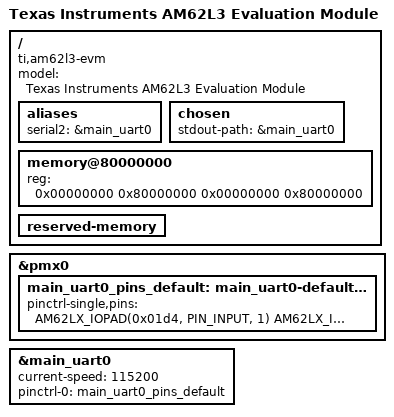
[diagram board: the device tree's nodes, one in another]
// SPDX-License-Identifier: GPL-2.0-only or MIT
/*
 * Device Tree file for the AM62L3 Evaluation Module
 * Copyright (C) 2024 Texas Instruments Incorporated - https://www.ti.com/
 *
 * Technical Reference Manual: https://www.ti.com/lit/ug/sprujb4/sprujb4.pdf
 */

/dts-v1/;

#include "k3-am62l3.dtsi"

/ {
	compatible = "ti,am62l3-evm", "ti,am62l3";
	model = "Texas Instruments AM62L3 Evaluation Module";

	aliases {
		serial2 = &main_uart0;
	};

	chosen {
		stdout-path = &main_uart0;
	};

	memory@80000000 {
		reg = <0x00000000 0x80000000 0x00000000 0x80000000>;
		device_type = "memory";
		bootph-all;
	};

	reserved-memory {
		ranges;
		#address-cells = <2>;
		#size-cells = <2>;
	};
};

&pmx0 {
	main_uart0_pins_default: main_uart0-default-pins {
		pinctrl-single,pins = <
			AM62LX_IOPAD(0x01d4, PIN_INPUT, 1)	  /* (D7)  UART0_RXD */
			AM62LX_IOPAD(0x01d8, PIN_OUTPUT, 1)	  /* (A6)  UART0_TXD */
		>;
		bootph-all;
	};
};

&main_uart0 {
	current-speed = <115200>;
	pinctrl-names = "default";
	pinctrl-0 = <&main_uart0_pins_default>;
	status = "okay";
	bootph-all;
};
